# ATSAMD09D14A register map
Vendor: Atmel Corporation; Series: SAMD09; File version: A
Atmel ATSAMD09D14A device: Cortex-M0+ Microcontroller with 16KB Flash, 4KB SRAM, QFN24_capless-pin package (refer to http://www.atmel.com/devices/SAMD09D14A.aspx for more)
CPU: CM0+ r0p1, little endian, no MPU, no FPU, VTOR, 2 interrupt priority bits
Registers are 32-bit, read-write, reset 0x0 unless marked. A register's access mark holds for its fields unless they carry their own. Offsets are from the block's base; lines under a group give offsets from that group; [hi:lo] are bit positions; {n}, {i} and the like mark numbered series; 'fields as' and 'values as' point back to an identical list; <NAME> marks a mode.

## Memory map
0x40000000 PAC0 size 0x8 — Peripheral Access Controller 0
0x40000400 PM size 0x80 — Power Manager
0x40000800 SYSCTRL size 0x80 — System Control
0x40000C00 GCLK size 0x10 — Generic Clock Generator
0x40001000 WDT size 0x10 — Watchdog Timer
0x40001400 RTC size 0x40 — Real-Time Counter
0x40001800 EIC size 0x40 — External Interrupt Controller
0x41000000 PAC1 size 0x8 — Peripheral Access Controller 1
0x41002000 DSU size 0x2000 — Device Service Unit
0x41004000 NVMCTRL size 0x80 — Non-Volatile Memory Controller
0x41004400 PORT size 0x200 — Port Module
0x41004800 DMAC size 0x80 — Direct Memory Access Controller
0x41006000 MTB size 0x1000 — Cortex-M0+ Micro-Trace Buffer
0x41007000 HMATRIX size 0x400 — HSB Matrix
0x42000000 PAC2 size 0x8 — Peripheral Access Controller 2
0x42000400 EVSYS size 0x80 — Event System Interface
0x42000800 SERCOM0 size 0x40 — Serial Communication Interface 0
0x42000C00 SERCOM1 size 0x40 — Serial Communication Interface 1
0x42001800 TC1 size 0x40 — Basic Timer Counter 1
0x42001C00 TC2 size 0x40 — Basic Timer Counter 2
0x42002000 ADC size 0x80 — Analog Digital Converter

## Interrupts
0 PM
1 SYSCTRL
2 WDT
3 RTC
4 EIC
5 NVMCTRL
6 DMAC
8 EVSYS
9 SERCOM0
10 SERCOM1
13 TC1
14 TC2
15 ADC

## DSU — Device Service Unit
Base 0x41002000; register names take the prefix DSU_
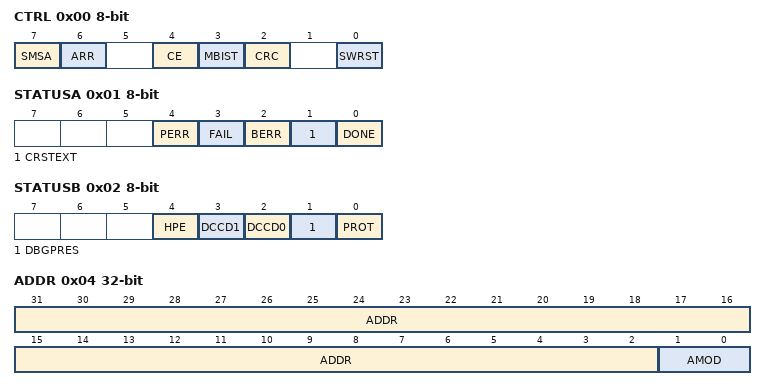
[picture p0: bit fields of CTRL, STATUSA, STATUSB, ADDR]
0x00 CTRL 8-bit wo — Control
  [7] SMSA — Start Memory Stream Access
  [6] ARR — Auxiliary Row Read
  [4] CE — Chip-Erase
  [3] MBIST — Memory built-in self-test
  [2] CRC — 32-bit Cyclic Redundancy Code
  [0] SWRST — Software Reset
0x01 STATUSA 8-bit
  [4] PERR — Protection Error
  [3] FAIL — Failure
  [2] BERR — Bus Error
  [1] CRSTEXT — CPU Reset Phase Extension
  [0] DONE
0x02 STATUSB 8-bit ro
  [4] HPE — Hot-Plugging Enable
  [3] DCCD1 — Debug Communication Channel 1 Dirty
  [2] DCCD0 — Debug Communication Channel 0 Dirty
  [1] DBGPRES — Debugger Present
  [0] PROT — Protected
0x04 ADDR — Address
  [31:2] ADDR — Address
  [1:0] AMOD — Access Mode
0x08 LENGTH
  [31:2] LENGTH
0x0C DATA
{0x10+4i} DCC{i} (i=0..1) — Debug Communication Channel n
  [31:0] DATA
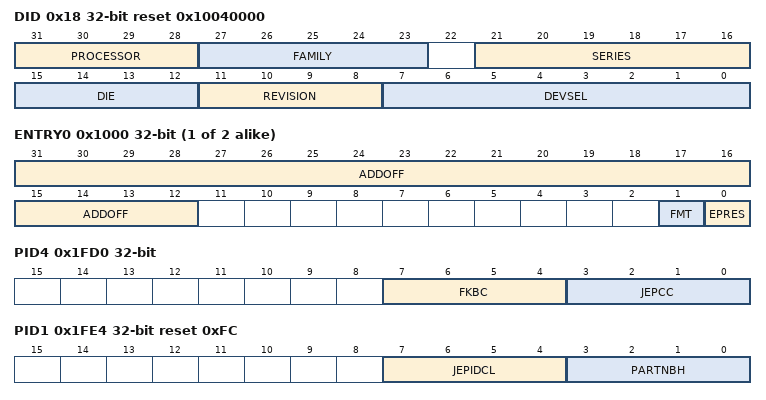
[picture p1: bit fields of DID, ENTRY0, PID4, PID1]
0x18 DID ro reset 0x10040000 — Device Identification
  [31:28] PROCESSOR
    0=Cortex-M0; 1=Cortex-M0+; 2=Cortex-M3; 3=Cortex-M4
  [27:23] FAMILY
    0=General purpose microcontroller; 1=PicoPower
  [21:16] SERIES
    0=Cortex-M0+ processor, basic feature set; 1=Cortex-M0+ processor, USB
  [15:12] DIE — Die Number
  [11:8] REVISION — Revision Number
  [7:0] DEVSEL — Device Select
{0xF0+4i} DCFG{i} (i=0..1) — Device Configuration
  [31:0] DCFG
{0x1000+4i} ENTRY{i} (i=0..1) ro — Coresight ROM Table Entry n
  [31:12] ADDOFF — Address Offset
  [1] FMT — Format
  [0] EPRES — Entry Present
0x1008 END ro — Coresight ROM Table End
  [31:0] END — End Marker
0x1FCC MEMTYPE ro — Coresight ROM Table Memory Type
  [0] SMEMP — System Memory Present
0x1FD0 PID4 ro — Peripheral Identification 4
  [7:4] FKBC — 4KB count
  [3:0] JEPCC — JEP-106 Continuation Code
{0x1FC0+4i} PID{i} ro (i=5..7) — Peripheral Identification {i}
0x1FE0 PID0 ro — Peripheral Identification 0
  [7:0] PARTNBL — Part Number Low
0x1FE4 PID1 ro reset 0xFC — Peripheral Identification 1
  [7:4] JEPIDCL — Low part of the JEP-106 Identity Code
  [3:0] PARTNBH — Part Number High
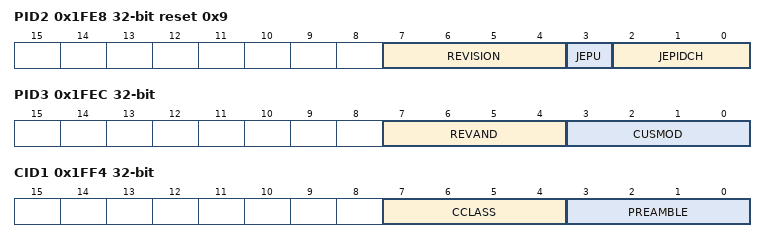
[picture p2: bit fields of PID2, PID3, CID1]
0x1FE8 PID2 ro reset 0x9 — Peripheral Identification 2
  [7:4] REVISION — Revision Number
  [3] JEPU — JEP-106 Identity Code is used
  [2:0] JEPIDCH — JEP-106 Identity Code High
0x1FEC PID3 ro — Peripheral Identification 3
  [7:4] REVAND — Revision Number
  [3:0] CUSMOD — ARM CUSMOD
0x1FF0 CID0 ro — Component Identification 0
  [7:0] PREAMBLEB0 — Preamble Byte 0
0x1FF4 CID1 ro — Component Identification 1
  [7:4] CCLASS — Component Class
  [3:0] PREAMBLE
0x1FF8 CID2 ro — Component Identification 2
  [7:0] PREAMBLEB2 — Preamble Byte 2
0x1FFC CID3 ro — Component Identification 3
  [7:0] PREAMBLEB3 — Preamble Byte 3

## Licence text in the file
============================================================================ Atmel Microcontroller Software Support ============================================================================ Copyright (c) 2015, Atmel Corporation . All rights reserved. . Redistribution and use in source and binary forms, with or without modification, are permitted provided that the following condition is met: - Redistributions of source code must retain the above copyright notice, this list of conditions and the disclaimer below. . Atmel's name may not be used to endorse or promote products derived from this software without specific prior written permission. . DISCLAIMER: THIS SOFTWARE IS PROVIDED BY ATMEL "AS IS" AND ANY EXPRESS OR. IMPLIED WARRANTIES, INCLUDING, BUT NOT LIMITED TO, THE IMPLIED WARRANTIES OF. MERCHANTABILITY, FITNESS FOR A PARTICULAR PURPOSE AND NON-INFRINGEMENT ARE. DISCLAIMED. IN NO EVENT SHALL ATMEL BE LIABLE FOR ANY DIRECT, INDIRECT, INCIDENTAL, SPECIAL, EXEMPLARY, OR CONSEQUENTIAL DAMAGES (INCLUDING, BUT NOT. LIMITED TO, PROCUREMENT OF SUBSTITUTE GOODS OR SERVICES; LOSS OF USE, DATA, OR PROFITS; OR BUSINESS INTERRUPTION) HOWEVER CAUSED AND ON ANY THEORY OF. LIABILITY, WHETHER IN CONTRACT, STRICT LIABILITY, OR TORT (INCLUDING. NEGLIGENCE OR OTHERWISE) ARISING IN ANY WAY OUT OF THE USE OF THIS SOFTWARE, EVEN IF ADVISED OF THE POSSIBILITY OF SUCH DAMAGE. ============================================================================
